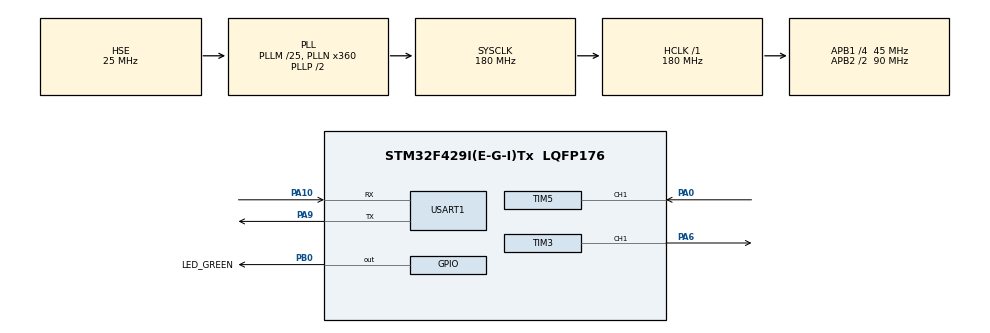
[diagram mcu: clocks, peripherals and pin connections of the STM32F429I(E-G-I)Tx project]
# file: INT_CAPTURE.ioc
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Mcu.Family=STM32F4
Mcu.Name=STM32F429I(E-G-I)Tx
Mcu.Package=LQFP176
NVIC.PriorityGroup=NVIC_PRIORITYGROUP_2
NVIC.TIM5_IRQn=true\:2\:0\:true\:false\:true
NVIC.USART1_IRQn=true\:2\:1\:true\:false\:true
PA0/WKUP.GPIO_ModeDefaultPP=GPIO_MODE_AF_PP
PA0/WKUP.GPIO_PuPd=GPIO_PULLDOWN
PA0/WKUP.GPIO_Speed=GPIO_SPEED_FREQ_VERY_HIGH
PA0/WKUP.Signal=S_TIM5_CH1
PA10.Mode=Asynchronous
PA10.Signal=USART1_RX
PA6.Signal=S_TIM3_CH1
PA9.Mode=Asynchronous
PA9.Signal=USART1_TX
PB0.GPIO_Label=LED_GREEN
PB0.GPIO_PuPd=GPIO_PULLUP
PB0.GPIO_Speed=GPIO_SPEED_FREQ_VERY_HIGH
PB0.PinState=GPIO_PIN_SET
PB0.Signal=GPIO_Output
PH0/OSC_IN.Mode=HSE-External-Oscillator
PH0/OSC_IN.Signal=RCC_OSC_IN
PH1/OSC_OUT.Mode=HSE-External-Oscillator
PH1/OSC_OUT.Signal=RCC_OSC_OUT
ProjectManager.HeapSize=0x200
ProjectManager.StackSize=0x400
ProjectManager.TargetToolchain=MDK-ARM V5
RCC.48MHZClocksFreq_Value=90000000
RCC.AHBFreq_Value=180000000
RCC.APB1CLKDivider=RCC_HCLK_DIV4
RCC.APB1Freq_Value=45000000
RCC.APB1TimFreq_Value=90000000
RCC.APB2CLKDivider=RCC_HCLK_DIV2
RCC.APB2Freq_Value=90000000
RCC.APB2TimFreq_Value=180000000
RCC.CortexFreq_Value=180000000
RCC.HCLKFreq_Value=180000000
RCC.HSE_VALUE=25000000
RCC.HSI_VALUE=16000000
RCC.LSE_VALUE=32768
RCC.PLLM=25
RCC.PLLN=360
RCC.PLLSourceVirtual=RCC_PLLSOURCE_HSE
RCC.SYSCLKFreq_VALUE=180000000
RCC.SYSCLKSource=RCC_SYSCLKSOURCE_PLLCLK
RCC.VCOOutputFreq_Value=360000000
SH.S_TIM3_CH1.0=TIM3_CH1,PWM Generation1 CH1
SH.S_TIM5_CH1.0=TIM5_CH1,Input_Capture1_from_TI1
TIM3.Period=200-1
TIM3.Prescaler=9000-1
TIM3.Pulse-PWM\ Generation1\ CH1=15
TIM5.Period=0xFFFFFFFF
TIM5.Prescaler=90-1
VP_TIM3_VS_ClockSourceINT.Mode=Internal
VP_TIM5_VS_ClockSourceINT.Mode=Internal
board=INT_CAPTURE

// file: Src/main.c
/**
  ******************************************************************************
  * File Name          : main.c
  * Description        : Main program body
  ******************************************************************************
  *
  * COPYRIGHT(c) 2020 STMicroelectronics
  *
  * Redistribution and use in source and binary forms, with or without modification,
  * are permitted provided that the following conditions are met:
  *   1. Redistributions of source code must retain the above copyright notice,
  *      this list of conditions and the following disclaimer.
  *   2. Redistributions in binary form must reproduce the above copyright notice,
  *      this list of conditions and the following disclaimer in the documentation
  *      and/or other materials provided with the distribution.
  *   3. Neither the name of STMicroelectronics nor the names of its contributors
  *      may be used to endorse or promote products derived from this software
  *      without specific prior written permission.
  *
  * THIS SOFTWARE IS PROVIDED BY THE COPYRIGHT HOLDERS AND CONTRIBUTORS "AS IS"
  * AND ANY EXPRESS OR IMPLIED WARRANTIES, INCLUDING, BUT NOT LIMITED TO, THE
  * IMPLIED WARRANTIES OF MERCHANTABILITY AND FITNESS FOR A PARTICULAR PURPOSE ARE
  * DISCLAIMED. IN NO EVENT SHALL THE COPYRIGHT HOLDER OR CONTRIBUTORS BE LIABLE
  * FOR ANY DIRECT, INDIRECT, INCIDENTAL, SPECIAL, EXEMPLARY, OR CONSEQUENTIAL
  * DAMAGES (INCLUDING, BUT NOT LIMITED TO, PROCUREMENT OF SUBSTITUTE GOODS OR
  * SERVICES; LOSS OF USE, DATA, OR PROFITS; OR BUSINESS INTERRUPTION) HOWEVER
  * CAUSED AND ON ANY THEORY OF LIABILITY, WHETHER IN CONTRACT, STRICT LIABILITY,
  * OR TORT (INCLUDING NEGLIGENCE OR OTHERWISE) ARISING IN ANY WAY OUT OF THE USE
  * OF THIS SOFTWARE, EVEN IF ADVISED OF THE POSSIBILITY OF SUCH DAMAGE.
  *
  ******************************************************************************
  */
#include "stm32f4xx_hal.h"
#include "tim.h"
#include "usart.h"
#include "gpio.h"

/* USER CODE BEGIN PV */
/* Private variables ---------------------------------------------------------*/

/* USER CODE END PV */

void SystemClock_Config(void);

/* USER CODE BEGIN PFP */
/* Private function prototypes -----------------------------------------------*/

/* USER CODE END PFP */

/* USER CODE BEGIN 0 */
extern u8  TIM5CH1_CAPTURE_STA;		//输入捕获状态
extern u32	TIM5CH1_CAPTURE_VAL;	//输入捕获值
/* USER CODE END 0 */

int main(void)
{

  /* USER CODE BEGIN 1 */
   long long temp=0;
  /* USER CODE END 1 */

  /* MCU Configuration----------------------------------------------------------*/

  /* Reset of all peripherals, Initializes the Flash interface and the Systick. */
  HAL_Init();

  /* Configure the system clock */
  SystemClock_Config();

  /* Initialize all configured peripherals */
  MX_GPIO_Init();
  MX_TIM3_Init();
  MX_TIM5_Init();
  MX_USART1_UART_Init();

  /* USER CODE BEGIN 2 */
  HAL_TIM_PWM_Start(&htim3,TIM_CHANNEL_1);

  //同时开启定时器输入捕获通道和使能捕获中断
  HAL_TIM_IC_Start_IT(&htim5,TIM_CHANNEL_1);
  //也可以下边两个函数分开使用
  //HAL_TIM_IC_Start(&htim5,TIM_CHANNEL_1);//开启输入捕获
  //__HAL_TIM_ENABLE_IT(&htim5,TIM_IT_UPDATE);//开启使能捕获中断

  /* USER CODE END 2 */
  HAL_GPIO_WritePin(LED_GREEN_GPIO_Port,LED_GREEN_Pin,GPIO_PIN_RESET);
  /* Infinite loop */
  while (1)
  {
  if(TIM5CH1_CAPTURE_STA&0X80)        //成功捕获到了一次高电平
	{
		temp=TIM5CH1_CAPTURE_STA&0X3F;
		temp*=0XFFFFFFFF;		 	    //溢出时间总和
		temp+=TIM5CH1_CAPTURE_VAL;      //得到总的高电平时间
		printf("HIGH:%lld us\r\n",temp);//打印总的高点平时间
		TIM5CH1_CAPTURE_STA=0;          //开启下一次捕获
	}
  }

}

/** System Clock Configuration
*/
void SystemClock_Config(void)
{

  RCC_OscInitTypeDef RCC_OscInitStruct;
  RCC_ClkInitTypeDef RCC_ClkInitStruct;

  __HAL_RCC_PWR_CLK_ENABLE();

  __HAL_PWR_VOLTAGESCALING_CONFIG(PWR_REGULATOR_VOLTAGE_SCALE1);

  RCC_OscInitStruct.OscillatorType = RCC_OSCILLATORTYPE_HSE;
  RCC_OscInitStruct.HSEState = RCC_HSE_ON;
  RCC_OscInitStruct.PLL.PLLState = RCC_PLL_ON;
  RCC_OscInitStruct.PLL.PLLSource = RCC_PLLSOURCE_HSE;
  RCC_OscInitStruct.PLL.PLLM = 25;
  RCC_OscInitStruct.PLL.PLLN = 360;
  RCC_OscInitStruct.PLL.PLLP = RCC_PLLP_DIV2;
  RCC_OscInitStruct.PLL.PLLQ = 4;
  HAL_RCC_OscConfig(&RCC_OscInitStruct);

  HAL_PWREx_EnableOverDrive();

  RCC_ClkInitStruct.ClockType = RCC_CLOCKTYPE_HCLK|RCC_CLOCKTYPE_SYSCLK
                              |RCC_CLOCKTYPE_PCLK1|RCC_CLOCKTYPE_PCLK2;
  RCC_ClkInitStruct.SYSCLKSource = RCC_SYSCLKSOURCE_PLLCLK;
  RCC_ClkInitStruct.AHBCLKDivider = RCC_SYSCLK_DIV1;
  RCC_ClkInitStruct.APB1CLKDivider = RCC_HCLK_DIV4;
  RCC_ClkInitStruct.APB2CLKDivider = RCC_HCLK_DIV2;
  HAL_RCC_ClockConfig(&RCC_ClkInitStruct, FLASH_LATENCY_5);

  HAL_SYSTICK_Config(HAL_RCC_GetHCLKFreq()/1000);

  HAL_SYSTICK_CLKSourceConfig(SYSTICK_CLKSOURCE_HCLK);

  /* SysTick_IRQn interrupt configuration */
  HAL_NVIC_SetPriority(SysTick_IRQn, 0, 0);
}

/************************ (C) COPYRIGHT STMicroelectronics *****END OF FILE****/
